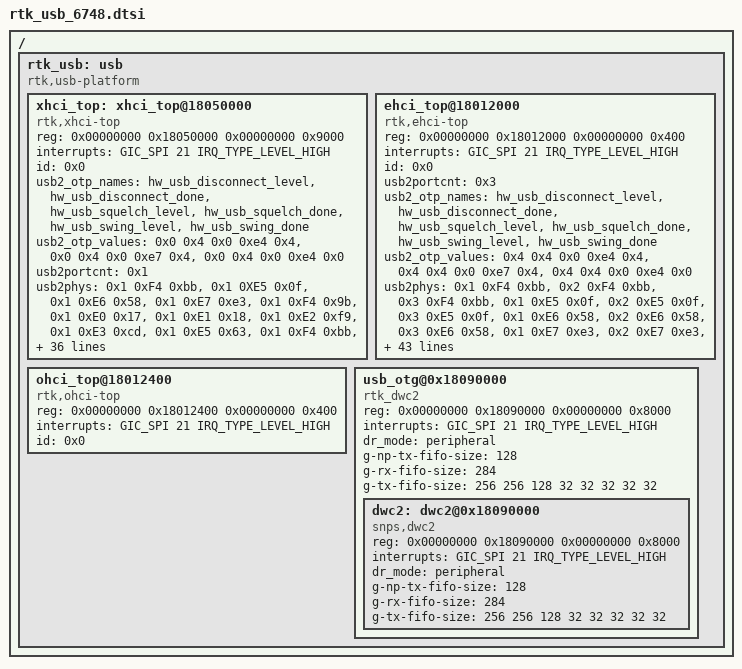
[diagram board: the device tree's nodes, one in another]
/*
 * RTK TV usb host driver device tree in the 64 bits version;
 * including the base address, parameters of phy etc.
 *
 */

/ {
	#address-cells = <1>;
	#size-cells = <1>;
	rtk_usb: usb {
		compatible = "rtk,usb-platform";
		#address-cells = <2>;
		#size-cells = <2>;
	       ranges;
		xhci_top: xhci_top@18050000 {
			compatible = "rtk,xhci-top";
			reg = <0x00000000 0x18050000 0x00000000 0x9000>;
			interrupts = <GIC_SPI 21 IRQ_TYPE_LEVEL_HIGH>;
			id = <0x0>;
			usb2_otp_names = "hw_usb_disconnect_level", "hw_usb_disconnect_done",
			                             "hw_usb_squelch_level", "hw_usb_squelch_done",
			                             "hw_usb_swing_level", "hw_usb_swing_done";
			                             
			usb2_otp_values = <0x0 0x4 0x0 0xe4 0x4>,/* otp_offset/bitsnum/page/reg/bits_offset */
							<0x0 0x4 0x0 0xe7 0x4>,
							<0x0 0x4 0x0 0xe4 0x0>;
							
			usb2portcnt = <0x1>;
			usb2phys = <0x1 0xF4 0xbb>,
				    <0x1 0XE5 0x0f>,
				    <0x1 0xE6 0x58>,
				    <0x1 0xE7 0xe3>,
				    <0x1 0xF4 0x9b>,
				    <0x1 0xE0 0x17>,
				    <0x1 0xE1 0x18>,
				    <0x1 0xE2 0xf9>,
				    <0x1 0xE3 0xcd>,
				    <0x1 0xE5 0x63>,
				    <0x1 0xF4 0xbb>,
				    <0x1 0xE3 0x03>,
				    <0x1 0xE4 0x44>,
				    <0x1 0xF4 0x9b>,
				    <0x1 0xE4 0x5b>,
				    <0x1 0xE7 0x51>,
				    <0x1 0xF4 0xbb>,
				    <0x1 0xE0 0x22>,
				    <0x1 0xE0 0x26>,
				    <0x1 0xF4 0x9b>,
				    <0x1 0xE4 0x8b>,
				    <0x1 0xE7 0x71>,
				    <0x1 0xE6 0x01>,
				    <0x1 0xF0 0xfc>,
				    <0x1 0xF1 0x8c>,
				    <0x1 0xF2 0x00>,
				    <0x1 0xF3 0x11>,
				    <0x1 0xF5 0x95>,
				    <0x1 0xF6 0x00>,
				    <0x1 0xF7 0xba>,
				    <0x1 0xF4 0xbb>,
				    <0x1 0xE2 0x00>,
				    <0x1 0xF6 0x29>,
				    <0x1 0xF7 0x40>,
				    <0x1 0xF4 0xdb>,
				    <0x1 0xE0 0xff>,
				    <0x1 0xE1 0xfb>,
				    <0x1 0xE2 0x00>,
				    <0x1 0xE3 0x00>,
				    <0x1 0xE4 0x15>,
				    <0x1 0xE5 0x81>,
				    <0x1 0xE6 0x53>,
				    <0x1 0xF4 0x9b>;
				    
		usb3portcnt = <0x1>;		    
		usb3phys =  <0x0 0x0 0x00 0x400c>,
				    <0x0 0x0 0x01 0xac86>,
				    <0x0 0x0 0x02 0x6042>,
				    <0x0 0x0 0x03 0x2771>,
				    <0x0 0x0 0x04 0x72f5>,
				    <0x0 0x0 0x05 0x2ad3>,
				    <0x0 0x0 0x06 0x001a>,
				    <0x0 0x0 0x07 0x2e00>,
				    <0x0 0x0 0x08 0x3591>,
				    <0x0 0x0 0x0A 0xb608>,
				    <0x0 0x0 0x0B 0xb905>,
				    <0x0 0x0 0x0C 0xc008>, 
				    <0x0 0x0 0x0D 0xef1e>,
				    <0x0 0x0 0x0E 0x1010>,
				    <0x0 0x0 0x0F 0x8d50>,
				    <0x0 0x0 0x10 0x000c>,
				    <0x0 0x0 0x11 0x4c10>,
				    <0x0 0x0 0x12 0x0000>,
				    <0x0 0x0 0x13 0x0c81>,
				    <0x0 0x0 0x14 0xde01>,
				    <0x0 0x0 0x15 0x0000>,
				    <0x0 0x0 0x16 0x0000>,
				    <0x0 0x0 0x17 0x0000>,
				    <0x0 0x0 0x18 0x0000>,
				    <0x0 0x0 0x19 0x6000>,
				    <0x0 0x0 0x1A 0x0085>,
				    <0x0 0x0 0x1B 0x2014>,
				    <0x0 0x0 0x1C 0xc900>,
				    <0x0 0x0 0x1D 0xa03f>,
				    <0x0 0x0 0x1E 0xc2e0>, 
				    <0x0 0x0 0x1F 0x7e00>,
				    <0x0 0x1 0x00 0x7058>,
				    <0x0 0x1 0x01 0xf545>, 
				    <0x0 0x1 0x02 0x0013>,
				    <0x0 0x1 0x03 0xbb66>,
				    <0x0 0x1 0x04 0x4470>,
				    <0x0 0x1 0x05 0x126c>, 
				    <0x0 0x1 0x06 0x840a>,
				    <0x0 0x1 0x07 0x01d6>,
				    <0x0 0x1 0x08 0xf802>,
				    <0x0 0x1 0x09 0xff00>, 
				    <0x0 0x1 0x0A 0x3041>,
				    <0x0 0x1 0x0B 0x8028>,
				    <0x0 0x1 0x0C 0xffff>, 
				    <0x0 0x1 0x0D 0xffff>,
				    <0x0 0x1 0x0E 0x0000>,
				    <0x0 0x1 0x0F 0x8600>;
		};

		ehci_top@18012000 {
			compatible = "rtk,ehci-top";
			reg = <0x00000000 0x18012000 0x00000000 0x400>;
            		interrupts = <GIC_SPI 21 IRQ_TYPE_LEVEL_HIGH>;
            		id = <0x0>;
            		usb2portcnt = <0x3>;
            		usb2_otp_names = "hw_usb_disconnect_level", "hw_usb_disconnect_done",
			                             "hw_usb_squelch_level", "hw_usb_squelch_done",
			                             "hw_usb_swing_level", "hw_usb_swing_done";
			                             
			usb2_otp_values = <0x4 0x4 0x0 0xe4 0x4>,/* otp_offset/bitsnum/page/reg/bits_offset */
							<0x4 0x4 0x0 0xe7 0x4>,
							<0x4 0x4 0x0 0xe4 0x0>;
			usb2phys = <0x1 0xF4 0xbb>,
				    <0x2 0xF4 0xbb>,
				    <0x3 0xF4 0xbb>,
				    <0x1 0xE5 0x0f>,
				    <0x2 0xE5 0x0f>,
				    <0x3 0xE5 0x0f>,
				    <0x1 0xE6 0x58>,
				    <0x2 0xE6 0x58>,
				    <0x3 0xE6 0x58>,
				    <0x1 0xE7 0xe3>,
				    <0x2 0xE7 0xe3>,
				    <0x3 0xE7 0xe3>,
				    <0x1 0xF4 0x9b>,  /* to page0 */
				    <0x2 0xF4 0x9b>,
				    <0x3 0xF4 0x9b>,
				    <0x1 0xE0 0x17>,  /*Z0*/
				    <0x2 0xE0 0x17>,
				    <0x3 0xE0 0x17>,
				    <0x1 0XE1 0x18>,
				    <0x2 0XE1 0x18>,
				    <0x3 0XE1 0x18>,
				    <0x1 0xE2 0xf9>,
				    <0x2 0xE2 0xf9>,
				    <0x3 0xE2 0xf9>,
				    <0x1 0xE3 0xcd>,
				    <0x2 0xE3 0xcd>,
				    <0x3 0xE3 0xcd>,
				    <0x1 0xE5 0x63>,  /* REG_DBS_SEL[1]=1: Double sensitivity 1.5X*/
				    <0x2 0xE5 0x63>,
				    <0x3 0xE5 0x63>,
				    <0x1 0xF4 0xbb>,  /* to page1*/
				    <0x2 0xF4 0xbb>,
				    <0x3 0xF4 0xbb>,
				    <0x1 0xE1 0x77>,
				    <0x2 0xE1 0x77>,
				    <0x3 0xE1 0x77>,
				    <0x1 0xF4 0xdb>,  /*to page2*/
				    <0x2 0xF4 0xdb>,
				    <0x3 0xF4 0xdb>,
				    <0x1 0xE7 0x44>,    /*bit[7:4]=4SENH OBJ bit[3:0]=8SEND OBJ*/
				    <0x2 0xE7 0x44>,
				    <0x3 0xE7 0x44>,
				    <0x1 0xF4 0x9b>,  /* to page0*/
				    <0x2 0xF4 0x9b>,
				    <0x3 0xF4 0x9b>,
				    <0x1 0xE4 0x5f>,  /* (first) bit[7:4]=disconnect level bit[3:0]=swing;*/
				    <0x2 0xE4 0x5f>,
				    <0x3 0xE4 0x5f>,
				    <0x1 0xE7 0x51>,  /* (first) bit[7:4]=deivce disconnect level (squelch)*/
				    <0x2 0xE7 0x51>,
				    <0x3 0xE7 0x51>,
				    <0x1 0xF4 0xbb>,  /* to page1*/
				    <0x2 0xF4 0xbb>,
				    <0x3 0xF4 0xbb>,
				    <0x1 0xE0 0x22>,    /*bit[2]=0Calibration sensitivity*/
				    <0x2 0xE0 0x22>,
				    <0x3 0xE0 0x22>,
				    <0x1 0xE0 0x26>,
				    <0x2 0xE0 0x26>,
				    <0x3 0xE0 0x26>,
				    <0x1 0xF4 0x9b>,  /* to page0*/
				    <0x2 0xF4 0x9b>,
				    <0x3 0xF4 0x9b>,
				    <0x1 0xE4 0x8f>,  /* port0 (second) bit[7:4]=6(disconnect level) bit[3:0]=8(swing)*/
				    <0x2 0xE4 0x8f>,  /* port1 (second) bit[7:4]=6(disconnect level) bit[3:0]=8(swing)*/
				    <0x3 0xE4 0x8f>,  /* port2 (second) bit[7:4]=6(disconnect level) bit[3:0]=8(swing)*/
				    <0x1 0xE7 0x71>,  /* (second) bit[7:4]=deivce disconnect level (squelch)*/
				    <0x2 0xE7 0x71>,
				    <0x3 0xE7 0x71>,
				    <0x1 0xE6 0x01>,
				    <0x2 0xE6 0x01>,
				    <0x3 0xE6 0x01>,
				    <0x1 0xF0 0xfc>,
				    <0x2 0xF0 0xfc>,
				    <0x3 0xF0 0xfc>,
				    <0x1 0xF1 0x8c>,
				    <0x2 0xF1 0x8c>,
				    <0x3 0xF1 0x8c>,
				    <0x1 0xF2 0x00>,
				    <0x2 0xF2 0x00>,
				    <0x3 0xF2 0x00>,
				    <0x1 0xF3 0x11>,
				    <0x2 0xF3 0x11>,
				    <0x3 0xF3 0x11>,
				    <0x1 0xF5 0x95>,    /*[bit7]deglitch _en=1*/
				    <0x2 0xF5 0x95>,    /*[bit7]deglitch _en=1*/
				    <0x3 0xF5 0x95>,    /*[bit7]deglitch _en=1*/
				    <0x1 0xF6 0x00>,
				    <0x2 0xF6 0x00>,
				    <0x3 0xF6 0x00>,
				    <0x1 0xF7 0xba>,    /*NSQ_HST=0x3; enable REG_tolerance(bit8)*/
				    <0x2 0xF7 0xba>,
				    <0x3 0xF7 0xba>,
				    <0x1 0xF4 0xbb>,  /* to page1*/
				    <0x2 0xF4 0xbb>,  /* to page1*/
				    <0x3 0xF4 0xbb>,  /* to page1*/
				    <0x1 0xE2 0x00>,
				    <0x2 0xE2 0x00>,
				    <0x3 0xE2 0x00>,
				    <0x1 0xE3 0x03>,
				    <0x2 0xE3 0x03>,
				    <0x3 0xE3 0x03>,
				    <0x1 0xE4 0x48>,
				    <0x2 0xE4 0x48>,
				    <0x3 0xE4 0x48>,
				    <0x1 0xF6 0x29>,
				    <0x2 0xF6 0x29>,
				    <0x3 0xF6 0x29>,
				    <0x1 0xF7 0x40>,
				    <0x2 0xF7 0x40>,
				    <0x3 0xF7 0x40>,
				    <0x1 0xF4 0xdb>,  /* to page2*/
				    <0x2 0xF4 0xdb>,  /* to page2*/
				    <0x3 0xF4 0xdb>,  /* to page2*/
				    <0x1 0xE0 0xff>,
				    <0x2 0xE0 0xff>,
				    <0x3 0xE0 0xff>,
				    <0x1 0xE1 0xfb>,
				    <0x2 0xE1 0xfb>,
				    <0x3 0xE1 0xfb>,
				    <0x1 0xE2 0x00>,
				    <0x2 0xE2 0x00>,
				    <0x3 0xE2 0x00>,
				    <0x1 0xE3 0x00>,
				    <0x2 0xE3 0x00>,
				    <0x3 0xE3 0x00>,
				    <0x1 0xE4 0x15>,
				    <0x2 0xE4 0x15>,
				    <0x3 0xE4 0x15>,
				    <0x1 0xE5 0x81>,
				    <0x2 0xE5 0x81>,
				    <0x3 0xE5 0x81>,
				    <0x1 0xE6 0x53>,
				    <0x2 0xE6 0x53>,
				    <0x3 0xE6 0x53>,
				    <0x1 0xF4 0x9b>,  /* to page0*/
				    <0x2 0xF4 0x9b>,
				    <0x3 0xF4 0x9b>;

		};

		ohci_top@18012400 {
			compatible = "rtk,ohci-top";
			reg = <0x00000000 0x18012400 0x00000000 0x400>;
			interrupts = <GIC_SPI 21 IRQ_TYPE_LEVEL_HIGH>;
			id = <0x0>;
		};

		usb_otg@0x18090000 {
			compatible = "rtk_dwc2";
			reg = <0x00000000 0x18090000 0x00000000 0x8000>;
			interrupts = <GIC_SPI 21 IRQ_TYPE_LEVEL_HIGH>;
			dr_mode ="peripheral";
			g-np-tx-fifo-size = <128>;
			g-rx-fifo-size = <284>;
			g-tx-fifo-size = <256 256 128 32 32 32 32 32>;			
			/**for dwc2 otg**/
			#address-cells = <2>;
			#size-cells = <2>;
			ranges;
			dwc2: dwc2@0x18090000 {
				compatible = "snps,dwc2";
				reg = <0x00000000 0x18090000 0x00000000 0x8000>;
				interrupts = <GIC_SPI 21 IRQ_TYPE_LEVEL_HIGH>;
				dr_mode ="peripheral";
				g-np-tx-fifo-size = <128>;
				g-rx-fifo-size = <284>;
				g-tx-fifo-size = <256 256 128 32 32 32 32 32>;
			};
		};
	};

  };
